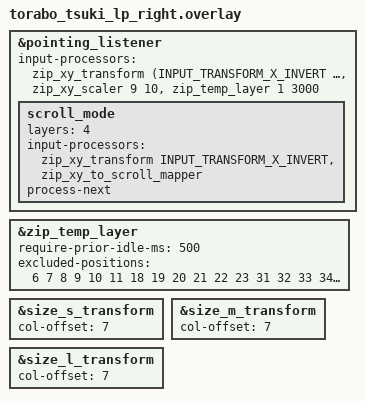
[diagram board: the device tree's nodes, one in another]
#include "torabo_tsuki_lp.dtsi"
#include <input/processors.dtsi>
#include <dt-bindings/zmk/input_transform.h>

&pointing_listener {
    input-processors = <
        &zip_xy_transform (INPUT_TRANSFORM_X_INVERT | INPUT_TRANSFORM_Y_INVERT)
        &zip_xy_scaler 9 10
        &zip_temp_layer 1 3000
    >;

    scroll_mode {
        layers = <4>;
        input-processors = <
            &zip_xy_transform INPUT_TRANSFORM_X_INVERT
            &zip_xy_to_scroll_mapper
        >;
        process-next;
    };
};

&zip_temp_layer {
    require-prior-idle-ms = <500>;
    excluded-positions = <6 7 8 9 10 11 18 19 20 21 22 23 31 32 33 34 35 36 37 45 46 47 48 49>;
};

&size_s_transform {
    col-offset = <7>;
};

&size_m_transform {
    col-offset = <7>;
};

&size_l_transform {
    col-offset = <7>;
};
